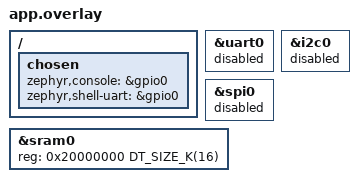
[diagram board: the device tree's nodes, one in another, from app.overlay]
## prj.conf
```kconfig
CONFIG_MAIN_STACK_SIZE=1024
CONFIG_SYSTEM_WORKQUEUE_STACK_SIZE=512
CONFIG_ISR_STACK_SIZE=256

CONFIG_SRAM_BASE_ADDRESS=0x20000000
CONFIG_SRAM_SIZE=16

# Clock control
CONFIG_CLOCK_CONTROL=y
CONFIG_CLOCK_CONTROL_NRF=y
CONFIG_CLOCK_CONTROL_NRF_K32SRC_RC=y

CONFIG_GPIO=y

CONFIG_SERIAL=n
CONFIG_CONSOLE=n
CONFIG_UART_CONSOLE=n

CONFIG_PM=n
```

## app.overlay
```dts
/ {
    /* Vô hiệu hóa UART mặc định của board ble400 để tránh tranh chấp chân */
    chosen {
        zephyr,console = &gpio0;
        zephyr,shell-uart = &gpio0;
    };
};

&uart0 {
    status = "disabled";
};

&i2c0 {
    status = "disabled";
};

&spi0 {
    status = "disabled";
};

&sram0 {
    reg = <0x20000000 DT_SIZE_K(16)>;
};
```

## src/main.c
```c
#include "nrf51.h"
#include "UART/uart.h"
#include "Radio/Radio.h"

#define nRF51822_TX 8
#define nRF51822_RX 9

#include <zephyr/kernel.h>
#include <zephyr/drivers/gpio.h>

uint8_t drone_id = 0;

int main(void){
    // Khởi tạo các ngoại vi
    drone_id = Auto_Get_Drone_ID();

    USART_Initialize(nRF51822_TX, nRF51822_RX);
    nRF51822_2411N_Configuration(&nRF51822_cfg);

    // LED đẫ set bên nRF51822_Config rồi

    uint8_t data[] = "HELLO";
    uint8_t data1[] = "HELL_NO";

    while(1){
        NRF_GPIO->OUTSET = (1 << LED_2411N);
        Drone_To_Master(data, sizeof(data), drone_id, 0);
        k_msleep(200);

        NRF_GPIO->OUTCLR = (1 << LED_2411N);
        Drone_To_Master(data1, sizeof(data1), drone_id, 0);
        k_msleep(200);
    }
    return 0;
}
```
